# WBZ351 register map
Vendor: Microchip
Registers are 32-bit, read-write, reset 0x0 unless marked. A register's access mark holds for its fields unless they carry their own. Addresses are absolute, and some are shared; only a register's first bit layout is shown; [hi:lo] are bit positions; {n}, {i} and the like mark numbered series; 'fields as' and 'values as' point back to an identical list.

## PCHE
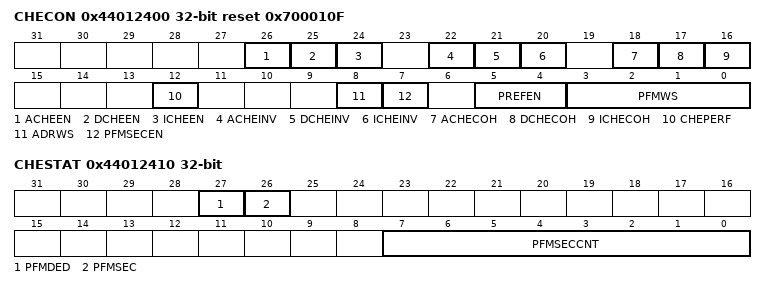
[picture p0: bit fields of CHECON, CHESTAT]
0x44012400 CHECON reset 0x700010F
  [26] ACHEEN, [25] DCHEEN, [24] ICHEEN, [22] ACHEINV, [21] DCHEINV, [20] ICHEINV, [18] ACHECOH, [17] DCHECOH, [16] ICHECOH, [12] CHEPERF, [8] ADRWS, [7] PFMSECEN, [5:4] PREFEN, [3:0] PFMWS
0x44012404 CHECONCLR
0x44012408 CHECONSET
0x4401240C CHECONINV
0x44012410 CHESTAT
  [27] PFMDED, [26] PFMSEC, [7:0] PFMSECCNT
0x44012414 CHESTATCLR
0x44012418 CHESTATSET
0x4401241C CHESTATINV
0x44012420 CHEHIT
0x44012424 CHEHITCLR
0x44012428 CHEHITSET
0x4401242C CHEHITINV
0x44012430 CHEMIS
0x44012434 CHEMISCLR
0x44012438 CHEMISSET
0x4401243C CHEMISINV

## PMU
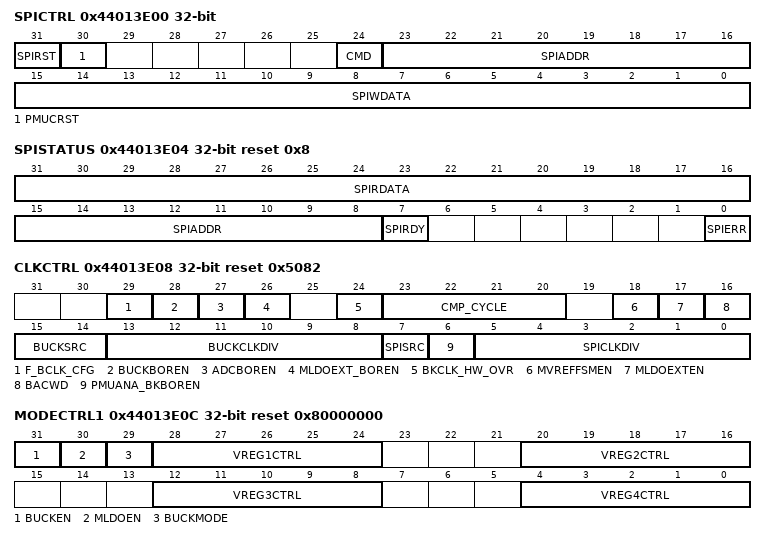
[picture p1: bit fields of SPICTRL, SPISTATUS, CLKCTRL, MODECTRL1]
0x44013E00 SPICTRL
  [31] SPIRST, [30] PMUCRST, [24] CMD, [23:16] SPIADDR, [15:0] SPIWDATA
0x44013E04 SPISTATUS reset 0x8
  [31:16] SPIRDATA, [15:8] SPIADDR, [7] SPIRDY, [0] SPIERR
0x44013E08 CLKCTRL reset 0x5082
  [29] F_BCLK_CFG, [28] BUCKBOREN, [27] ADCBOREN, [26] MLDOEXT_BOREN, [24] BKCLK_HW_OVR, [23:20] CMP_CYCLE, [18] MVREFFSMEN, [17] MLDOEXTEN, [16] BACWD, [15:14] BUCKSRC, [13:8] BUCKCLKDIV, [7] SPISRC, [6] PMUANA_BKBOREN, [5:0] SPICLKDIV
0x44013E0C MODECTRL1 reset 0x80000000
  [31] BUCKEN, [30] MLDOEN, [29] BUCKMODE, [36-8n:32-8n] VREG{n}CTRL (n=1..4)
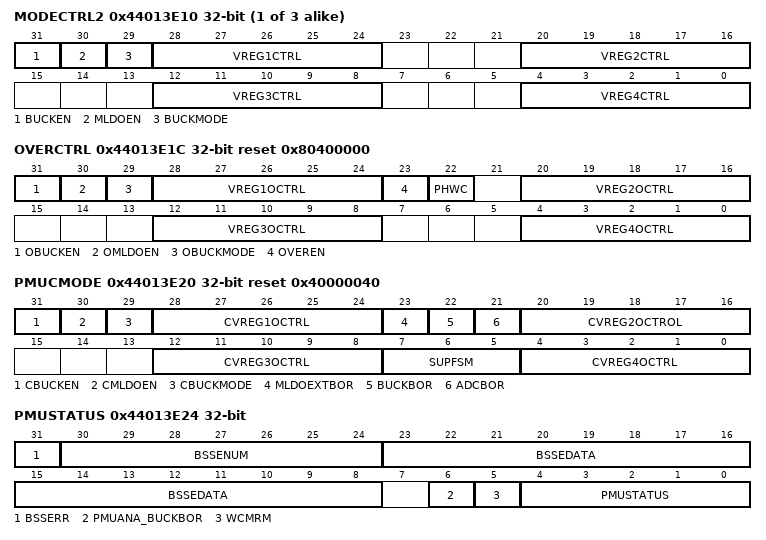
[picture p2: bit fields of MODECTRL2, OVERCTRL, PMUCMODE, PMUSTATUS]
{0x44013E08+4i} MODECTRL{i} (i=2..4)
  fields as MODECTRL1
0x44013E1C OVERCTRL reset 0x80400000
  [31] OBUCKEN, [30] OMLDOEN, [29] OBUCKMODE, [36-8n:32-8n] VREG{n}OCTRL (n=1..4), [23] OVEREN, [22] PHWC
0x44013E20 PMUCMODE reset 0x40000040
  [31] CBUCKEN, [30] CMLDOEN, [29] CBUCKMODE, [28:24] CVREG1OCTRL, [23] MLDOEXTBOR, [22] BUCKBOR, [21] ADCBOR, [20:16] CVREG2OCTROL, [12:8] CVREG3OCTRL, [7:5] SUPFSM, [4:0] CVREG4OCTRL
0x44013E24 PMUSTATUS
  [31] BSSERR, [30:24] BSSENUM, [23:8] BSSEDATA, [6] PMUANA_BUCKBOR, [5] WCMRM, [4:0] PMUSTATUS
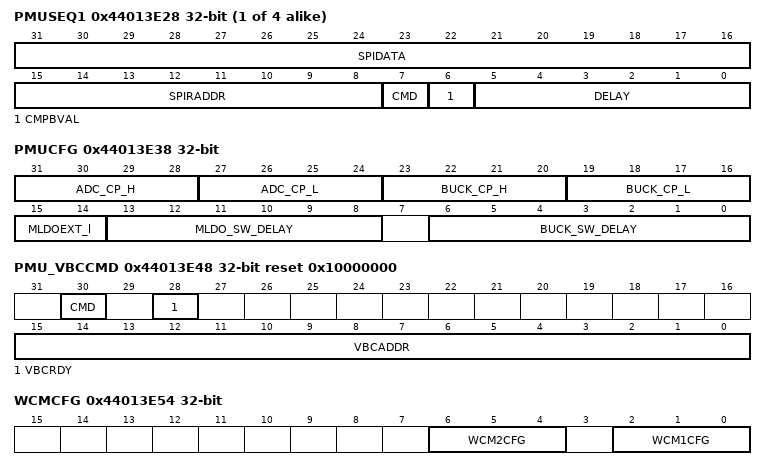
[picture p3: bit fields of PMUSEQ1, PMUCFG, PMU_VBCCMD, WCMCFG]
{0x44013E24+4i} PMUSEQ{i} (i=1..4)
  [31:16] SPIDATA, [15:8] SPIRADDR, [7] CMD, [6] CMPBVAL, [5:0] DELAY
0x44013E38 PMUCFG
  [31:28] ADC_CP_H, [27:24] ADC_CP_L, [23:20] BUCK_CP_H, [19:16] BUCK_CP_L, [15:14] MLDOEXT_l, [13:8] MLDO_SW_DELAY, [6:0] BUCK_SW_DELAY
0x44013E48 PMU_VBCCMD reset 0x10000000
  [30] CMD, [28] VBCRDY, [15:0] VBCADDR
0x44013E4C PMU_VBCWDATA
0x44013E50 PMU_VBCRDATA
0x44013E54 WCMCFG
  [6:4] WCM2CFG, [2:0] WCM1CFG
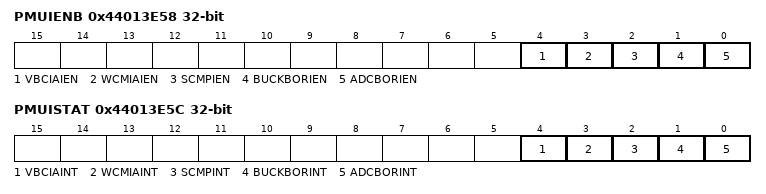
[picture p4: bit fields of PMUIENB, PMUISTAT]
0x44013E58 PMUIENB
  [4] VBCIAIEN, [3] WCMIAIEN, [2] SCMPIEN, [1] BUCKBORIEN, [0] ADCBORIEN
0x44013E5C PMUISTAT
  [4] VBCIAINT, [3] WCMIAINT, [2] SCMPINT, [1] BUCKBORINT, [0] ADCBORINT
0x44013E60 WCMSIZ
  [9:8] SRAM1_SIZ
    0=NO_SRAM_RETENTION (FlexRAM is completely powered OFF); 1=16K_SRAM (16K Flex RAM available in retention); 2=32K_SRAM (32K Flex RAM available in retention)

## ITM
{0xE0000000+4i} PORT{i} wo reset not defined (i=0..31)
  [31:0] PORT
0xE0000E00 TER reset not defined
0xE0000E40 TPR reset not defined
  [3:0] PRIVMASK
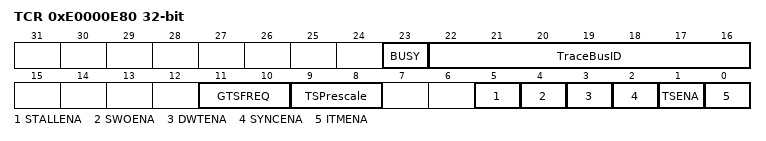
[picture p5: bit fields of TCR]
0xE0000E80 TCR reset not defined
  [23] BUSY, [22:16] TraceBusID, [11:10] GTSFREQ, [9:8] TSPrescale, [5] STALLENA, [4] SWOENA, [3] DWTENA, [2] SYNCENA, [1] TSENA, [0] ITMENA
0xE0000EF8 IWR wo reset not defined
  [0] ATVALIDM
0xE0000EFC IRR ro reset not defined
  [0] ATREADYM
0xE0000FD0 PID4 ro reset 0x4
{0xE0000FC0+4i} PID{i} ro (i=5..7)
0xE0000FE0 PID0 ro reset 0x1
0xE0000FE4 PID1 ro reset 0xB0
0xE0000FE8 PID2 ro reset 0x3B
0xE0000FEC PID3 ro
0xE0000FF0 CID0 ro reset 0xD
0xE0000FF4 CID1 ro reset 0xE0
0xE0000FF8 CID2 ro reset 0x5
0xE0000FFC CID3 ro reset 0xB1

## DWT
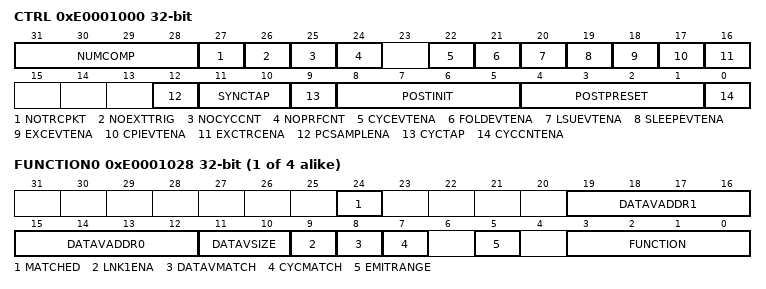
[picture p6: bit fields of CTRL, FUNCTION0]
0xE0001000 CTRL reset not defined
  [31:28] NUMCOMP, [27] NOTRCPKT, [26] NOEXTTRIG, [25] NOCYCCNT, [24] NOPRFCNT, [22] CYCEVTENA, [21] FOLDEVTENA, [20] LSUEVTENA, [19] SLEEPEVTENA, [18] EXCEVTENA, [17] CPIEVTENA, [16] EXCTRCENA, [12] PCSAMPLENA, [11:10] SYNCTAP, [9] CYCTAP, [8:5] POSTINIT, [4:1] POSTPRESET, [0] CYCCNTENA
0xE0001004 CYCCNT reset not defined
0xE0001008 CPICNT reset not defined
  [7:0] CPICNT
0xE000100C EXCCNT reset not defined
  [7:0] EXCCNT
0xE0001010 SLEEPCNT reset not defined
  [7:0] SLEEPCNT
0xE0001014 LSUCNT reset not defined
  [7:0] LSUCNT
0xE0001018 FOLDCNT reset not defined
  [7:0] FOLDCNT
0xE000101C PCSR ro reset not defined
{0xE0001020+0x10*i} COMP{i} reset not defined (i=0..3)
{0xE0001024+0x10*i} MASK{i} reset not defined (i=0..3)
  [4:0] MASK
{0xE0001028+0x10*i} FUNCTION{i} reset not defined (i=0..3)
  [24] MATCHED, [19:16] DATAVADDR1, [15:12] DATAVADDR0, [11:10] DATAVSIZE, [9] LNK1ENA, [8] DATAVMATCH, [7] CYCMATCH, [5] EMITRANGE, [3:0] FUNCTION
